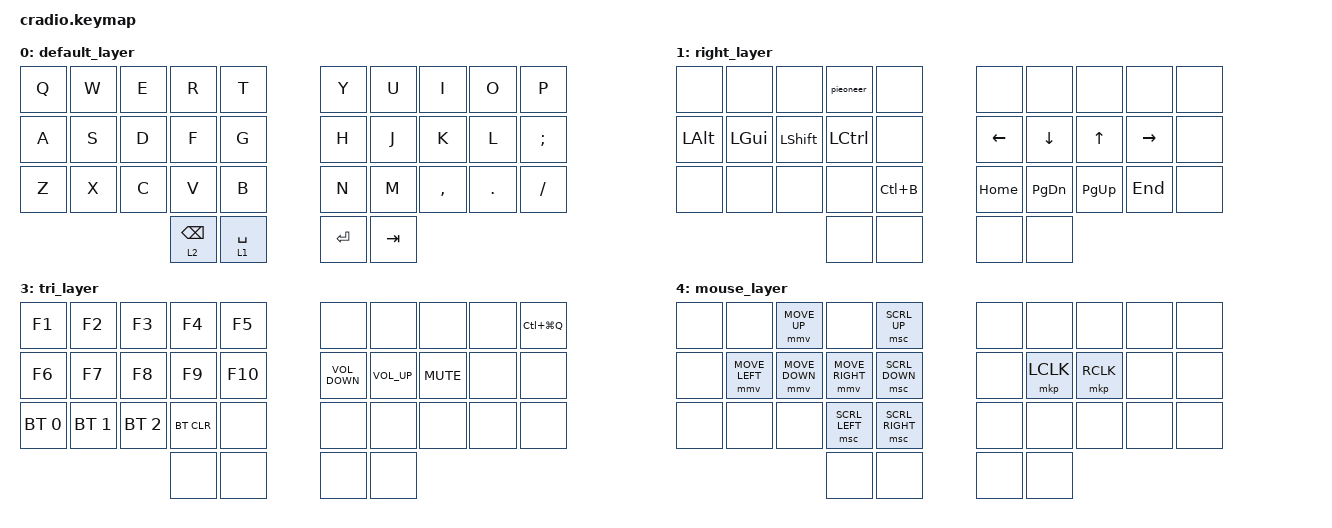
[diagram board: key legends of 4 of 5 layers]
// Copyright (c) 2022 The ZMK Contributors
// SPDX-License-Identifier: MIT

#include <behaviors.dtsi>
#include <dt-bindings/zmk/bt.h>
#include <dt-bindings/zmk/keys.h>
#include <dt-bindings/zmk/pointing.h>

#define MOUSELAYER 4

// Home row mods macro
#define HRML(k1,k2,k3,k4) &ht LALT k1 &ht LGUI k2 &ht LSHFT k3 &ht LCTRL k4
/* #define HRMR(k1,k2,k3,k4) &ht RGUI k1  &ht RCTRL k2  &ht RALT k3  &ht RSHFT k4 */

/ {
    behaviors {
        ht: hold_tap {
            compatible = "zmk,behavior-hold-tap";
            #binding-cells = <2>;
            flavor = "tap-preferred";
            tapping-term-ms = <220>;
            quick-tap-ms = <150>;
            require-prior-idle-ms = <100>;
            bindings = <&kp>, <&kp>;
        };
        lt_repeat: lt_repeat {
            compatible = "zmk,behavior-hold-tap";
            #binding-cells = <2>;
            flavor = "hold-preferred";
            tapping-term-ms = <200>;
            quick-tap-ms = <200>; 
            bindings = <&mo>, <&kp>;
        };
    };

    /* conditional_layers { */
    /*     compatible = "zmk,conditional-layers"; */
    /**/
    /*     tri_layer { */
    /*         if-layers = <1 2>; */
    /*         then-layer = <3>; */
    /*     }; */
    /* }; */

/*     Left Hand               Right Hand */
/* ╭───┬───┬───┬───┬───╮   ╭───┬───┬───┬───┬───╮ */
/* │ 0 │ 1 │ 2 │ 3 │ 4 │   │ 5 │ 6 │ 7 │ 8 │ 9 │  (상단) */
/* ├───┼───┼───┼───┼───┤   ├───┼───┼───┼───┼───┤ */
/* │10 │11 │12 │13 │14 │   │15 │16 │17 │18 │19 │  (중단/홈) */
/* ├───┼───┼───┼───┼───┤   ├───┼───┼───┼───┼───┤ */
/* │20 │21 │22 │23 │24 │   │25 │26 │27 │28 │29 │  (하단) */
/* ╰───┴───┴───┼───┼───┤   ├───┼───┴───┴───┴───╯ */
/*             │30 │31 │   │32 │33 │              (엄지) */
/*             ╰───┴───╯   ╰───┴───╯ */
    combos {
        compatible = "zmk,combos";

        lalt {
            bindings = <&kp LEFT_ALT>;
            key-positions = <10 11>;
            layers = <0>;
        };

        lgui {
            bindings = <&kp LEFT_GUI>;
            key-positions = <11 12>;
            layers = <0>;
            slow-release;
        };

        lshift {
            bindings = <&kp LSHIFT>;
            key-positions = <12 13>;
            layers = <0>;
        };

        lctrl {
            bindings = <&kp LEFT_CONTROL>;
            key-positions = <13 14>;
            layers = <0>;
            slow-release;
        };
        ltmuxleader {
            bindings = <&kp LC(B)>;
            key-positions = <13 24>;
            layers = <0>;
        };

        rctrl {
            bindings = <&kp RIGHT_CONTROL>;
            key-positions = <15 16>;
            layers = <0>;
        };

        rshift {
            bindings = <&kp RSHIFT>;
            key-positions = <16 17>;
            layers = <0>;
        };

        rgui {
            bindings = <&kp RGUI>;
            key-positions = <17 18>;
        };

        ralt {
            bindings = <&kp RIGHT_ALT>;
            key-positions = <19 18>;
            layers = <0>;
        };

        capslock {
            bindings = <&kp CLCK>;
            key-positions = <1 2>;
            layers = <0>;
            require-prior-idle-ms = <100>;
        };

        esc {
            bindings = <&kp ESC>;
            key-positions = <7 8>;
            layers = <0>;
            require-prior-idle-ms = <100>;
        };
    };

    macros {
        pieoneer: pieoneer {
            compatible = "zmk,behavior-macro";
            #binding-cells = <0>;
            bindings = <&kp LC(TAB)>;
            label = "PIEONEER";
        };
    };

    keymap {
        compatible = "zmk,keymap";

        default_layer {
            bindings = <
&kp Q  &kp W  &kp E  &kp R       &kp T          &kp Y      &kp U    &kp I      &kp O    &kp P
&kp A  &kp S  &kp D  &kp F       &kp G          &kp H      &kp J    &kp K      &kp L    &kp SEMI
&kp Z  &kp X  &kp C  &kp V       &kp B          &kp N      &kp M    &kp COMMA  &kp DOT  &kp FSLH
              &lt_repeat 2 BSPC  &lt 1 SPACE    &kp ENTER  &kp TAB
            >;
        };

        right_layer {
            bindings = <
&none     &none     &none      &pieoneer  &none        &none     &none          &none        &none      &none
&kp LALT  &kp LGUI  &kp LSHFT  &kp LCTRL  &none        &kp LEFT  &kp DOWN       &kp UP       &kp RIGHT  &none
&none     &none     &none      &none      &kp LC(B)    &kp HOME  &kp PAGE_DOWN  &kp PAGE_UP  &kp END    &none
                               &none      &none        &none     &none
            >;
        };

        left_layer {
            bindings = <
&kp NUMBER_1  &kp NUMBER_2  &kp NUMBER_3  &kp NUMBER_4  &kp N5    &none     &kp MINUS  &kp EQUAL  &kp BACKSLASH  &kp GRAVE
HRML(N6,      NUMBER_7,     N8,           N9)           &kp N0    &none     &kp RCTRL  &kp RSHFT  &kp RIGHT_GUI  &kp RIGHT_ALT
&none         &none         &none         &none         &none     &kp LBKT  &kp RBKT   &kp COMMA  &kp DOT        &kp SQT
                                          &none         &mo 3     &mo 4     &mo 3
            >;
        };

        tri_layer {
            bindings = <
&kp F1        &kp F2        &kp F3        &kp F4      &kp F5     &none              &none            &none       &none  &kp LC(LG(Q))
&kp F6        &kp F7        &kp F8        &kp F9      &kp F10    &kp C_VOLUME_DOWN  &kp C_VOLUME_UP  &kp K_MUTE  &none  &none
&bt BT_SEL 0  &bt BT_SEL 1  &bt BT_SEL 2  &bt BT_CLR  &none      &none              &none            &none       &none  &none
                                          &none       &none      &none              &none
            >;
        };

        mouse_layer {
            bindings = <
&none  &none           &mmv MOVE_UP    &none            &msc SCRL_UP       &none  &none      &none      &none  &none
&none  &mmv MOVE_LEFT  &mmv MOVE_DOWN  &mmv MOVE_RIGHT  &msc SCRL_DOWN     &none  &mkp LCLK  &mkp RCLK  &none  &none
&none  &none           &none           &msc SCRL_LEFT   &msc SCRL_RIGHT    &none  &none      &none      &none  &none
                                       &none            &none              &none  &none
            >;
        };
    };
};
